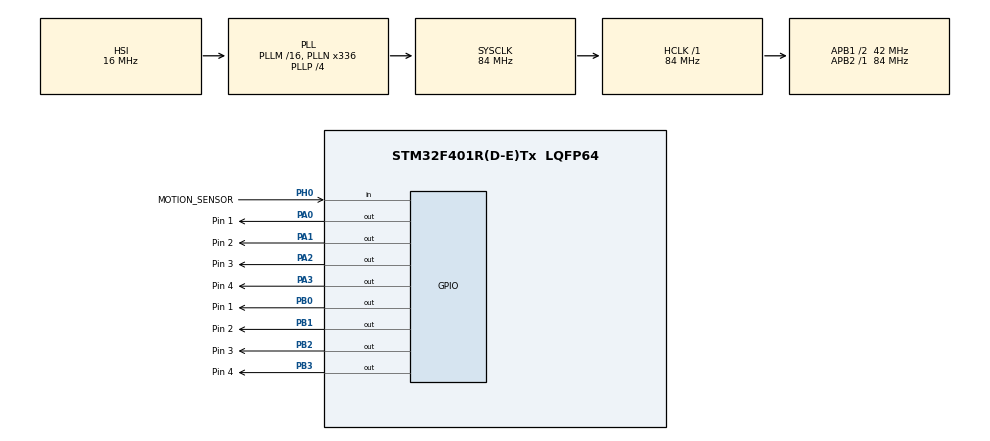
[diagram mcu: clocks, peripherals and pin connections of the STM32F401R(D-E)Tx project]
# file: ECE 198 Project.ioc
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Mcu.Family=STM32F4
Mcu.Name=STM32F401R(D-E)Tx
Mcu.Package=LQFP64
NVIC.PriorityGroup=NVIC_PRIORITYGROUP_0
PA0-WKUP.GPIO_Label=Pin 1
PA0-WKUP.Signal=GPIO_Output
PA1.GPIO_Label=Pin 2
PA1.Signal=GPIO_Output
PA2.GPIO_Label=Pin 3
PA2.Signal=GPIO_Output
PA3.GPIO_Label=Pin 4
PA3.Signal=GPIO_Output
PB0.GPIO_Label=Pin 1
PB0.Signal=GPIO_Output
PB1.GPIO_Label=Pin 2
PB1.Signal=GPIO_Output
PB2.GPIO_Label=Pin 3
PB2.Signal=GPIO_Output
PB3.GPIO_Label=Pin 4
PB3.Signal=GPIO_Output
PH0\ -\ OSC_IN.GPIO_Label=MOTION_SENSOR
PH0\ -\ OSC_IN.Signal=GPIO_Input
ProjectManager.HeapSize=0x200
ProjectManager.StackSize=0x400
ProjectManager.TargetToolchain=STM32CubeIDE
RCC.48MHZClocksFreq_Value=48000000
RCC.AHBFreq_Value=84000000
RCC.APB1CLKDivider=RCC_HCLK_DIV2
RCC.APB1Freq_Value=42000000
RCC.APB1TimFreq_Value=84000000
RCC.APB2Freq_Value=84000000
RCC.APB2TimFreq_Value=84000000
RCC.CortexFreq_Value=84000000
RCC.HCLKFreq_Value=84000000
RCC.HSE_VALUE=8000000
RCC.HSI_VALUE=16000000
RCC.PLLN=336
RCC.PLLP=RCC_PLLP_DIV4
RCC.PLLQ=7
RCC.SYSCLKFreq_VALUE=84000000
RCC.SYSCLKSource=RCC_SYSCLKSOURCE_PLLCLK
RCC.VCOOutputFreq_Value=336000000
board=NUCLEO-F401RE

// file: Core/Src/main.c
/* USER CODE BEGIN Header */
/**
  ******************************************************************************
  * @file           : main.c
  * @brief          : Main program body
  ******************************************************************************
  * @attention
  *
  * Copyright (c) 2023 STMicroelectronics.
  * All rights reserved.
  *
  * This software is licensed under terms that can be found in the LICENSE file
  * in the root directory of this software component.
  * If no LICENSE file comes with this software, it is provided AS-IS.
  *
  ******************************************************************************
  */
/* USER CODE END Header */
#include "main.h"

void SystemClock_Config(void);
static void MX_GPIO_Init(void);

int main(void)
{
  /* USER CODE BEGIN 1 */
	while (1) {
	        if (check_motion_sensor()) {
	            move_both_stepper_motors();
	        }
	}
  /* USER CODE END 1 */

  /* MCU Configuration--------------------------------------------------------*/

  /* Reset of all peripherals, Initializes the Flash interface and the Systick. */
  HAL_Init();

  /* Configure the system clock */
  SystemClock_Config();

  /* Initialize all configured peripherals */
  MX_GPIO_Init();

  /* Infinite loop */
  while (1){

  }
}

void SystemClock_Config(void)
{
  RCC_OscInitTypeDef RCC_OscInitStruct = {0};
  RCC_ClkInitTypeDef RCC_ClkInitStruct = {0};

  /** Configure the main internal regulator output voltage
  */
  __HAL_RCC_PWR_CLK_ENABLE();
  __HAL_PWR_VOLTAGESCALING_CONFIG(PWR_REGULATOR_VOLTAGE_SCALE2);

  /** Initializes the RCC Oscillators according to the specified parameters
  * in the RCC_OscInitTypeDef structure.
  */
  RCC_OscInitStruct.OscillatorType = RCC_OSCILLATORTYPE_HSI;
  RCC_OscInitStruct.HSIState = RCC_HSI_ON;
  RCC_OscInitStruct.HSICalibrationValue = RCC_HSICALIBRATION_DEFAULT;
  RCC_OscInitStruct.PLL.PLLState = RCC_PLL_ON;
  RCC_OscInitStruct.PLL.PLLSource = RCC_PLLSOURCE_HSI;
  RCC_OscInitStruct.PLL.PLLM = 16;
  RCC_OscInitStruct.PLL.PLLN = 336;
  RCC_OscInitStruct.PLL.PLLP = RCC_PLLP_DIV4;
  RCC_OscInitStruct.PLL.PLLQ = 7;
  if (HAL_RCC_OscConfig(&RCC_OscInitStruct) != HAL_OK)
  {
    Error_Handler();
  }

  /** Initializes the CPU, AHB and APB buses clocks
  */
  RCC_ClkInitStruct.ClockType = RCC_CLOCKTYPE_HCLK|RCC_CLOCKTYPE_SYSCLK
                              |RCC_CLOCKTYPE_PCLK1|RCC_CLOCKTYPE_PCLK2;
  RCC_ClkInitStruct.SYSCLKSource = RCC_SYSCLKSOURCE_PLLCLK;
  RCC_ClkInitStruct.AHBCLKDivider = RCC_SYSCLK_DIV1;
  RCC_ClkInitStruct.APB1CLKDivider = RCC_HCLK_DIV2;
  RCC_ClkInitStruct.APB2CLKDivider = RCC_HCLK_DIV1;

  if (HAL_RCC_ClockConfig(&RCC_ClkInitStruct, FLASH_LATENCY_2) != HAL_OK)
  {
    Error_Handler();
  }
}

static void MX_GPIO_Init(void)
{
  GPIO_InitTypeDef GPIO_InitStruct = {0};

  /* GPIO Ports Clock Enable */
  __HAL_RCC_GPIOH_CLK_ENABLE();
  __HAL_RCC_GPIOA_CLK_ENABLE();
  __HAL_RCC_GPIOB_CLK_ENABLE();

  /*Configure GPIO pin Output Level */
  HAL_GPIO_WritePin(GPIOA, Pin_1_Pin|Pin_2_Pin|Pin_3_Pin|Pin_4_Pin, GPIO_PIN_RESET);

  /*Configure GPIO pin Output Level */
  HAL_GPIO_WritePin(GPIOB, Pin_1B0_Pin|Pin_2B1_Pin|Pin_3B2_Pin|Pin_4B3_Pin, GPIO_PIN_RESET);

  /*Configure GPIO pin : MOTION_SENSOR_Pin */
  GPIO_InitStruct.Pin = MOTION_SENSOR_Pin;
  GPIO_InitStruct.Mode = GPIO_MODE_INPUT;
  GPIO_InitStruct.Pull = GPIO_NOPULL;
  HAL_GPIO_Init(MOTION_SENSOR_GPIO_Port, &GPIO_InitStruct);

  /*Configure GPIO pins : Pin_1_Pin Pin_2_Pin Pin_3_Pin Pin_4_Pin */
  GPIO_InitStruct.Pin = Pin_1_Pin|Pin_2_Pin|Pin_3_Pin|Pin_4_Pin;
  GPIO_InitStruct.Mode = GPIO_MODE_OUTPUT_PP;
  GPIO_InitStruct.Pull = GPIO_NOPULL;
  GPIO_InitStruct.Speed = GPIO_SPEED_FREQ_LOW;
  HAL_GPIO_Init(GPIOA, &GPIO_InitStruct);

  /*Configure GPIO pins : Pin_1B0_Pin Pin_2B1_Pin Pin_3B2_Pin Pin_4B3_Pin */
  GPIO_InitStruct.Pin = Pin_1B0_Pin|Pin_2B1_Pin|Pin_3B2_Pin|Pin_4B3_Pin;
  GPIO_InitStruct.Mode = GPIO_MODE_OUTPUT_PP;
  GPIO_InitStruct.Pull = GPIO_NOPULL;
  GPIO_InitStruct.Speed = GPIO_SPEED_FREQ_LOW;
  HAL_GPIO_Init(GPIOB, &GPIO_InitStruct);

}

void Error_Handler(void)
{
  __disable_irq();
  while (1)
  {
  }
}
